# ATSAMA5D225CD1M device description
Architecture: CORTEX-A5; Family: SAMA5; Series: SAMA5D2
Registers are 32-bit, read-write, no defined reset value unless marked. A register's access mark holds for its fields unless they carry their own. Offsets are from the block's base; [hi:lo] are bit positions; {n}, {i} and the like mark numbered series.

## ACC — Analog Comparator Controller
Instances: ACC 0xF804A000
0x00 ACC_CR wo — Control Register
  [0] SWRST — Software Reset
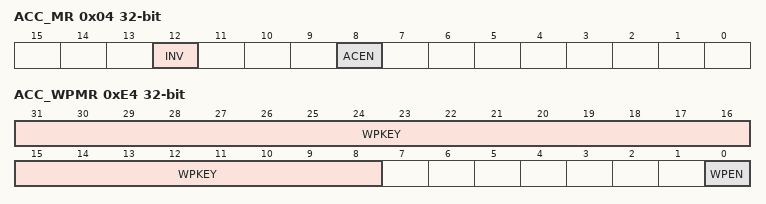
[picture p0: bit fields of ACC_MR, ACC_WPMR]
0x04 ACC_MR — Mode Register
  [12] INV — Invert Comparator Output
    0=DIS (Analog comparator output is directly processed.); 1=EN (Analog comparator output is inverted prior to being processed.)
  [8] ACEN — Analog Comparator Enable
    0=DIS (Analog comparator disabled.); 1=EN (Analog comparator enabled.)
0xE4 ACC_WPMR — Write Protection Mode Register
  [31:8] WPKEY — Write Protection Key
    0x414343=PASSWD (Writing any other value in this field aborts the write operation of the WPEN bit.Always reads as 0.)
  [0] WPEN — Write Protection Enable
0xE8 ACC_WPSR ro — Write Protection Status Register
  [0] WPVS — Write Protection Violation Status

## AESB — Advanced Encryption Standard Bridge
Instances: AESB 0xF001C000
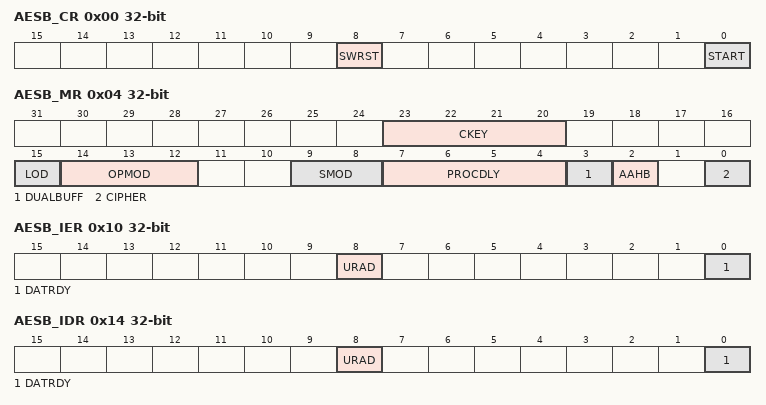
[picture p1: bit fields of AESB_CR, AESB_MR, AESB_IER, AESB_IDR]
0x00 AESB_CR wo — Control Register
  [8] SWRST — Software Reset
  [0] START — Start Processing
0x04 AESB_MR — Mode Register
  [23:20] CKEY — Key
    14=PASSWD (This field must be written with 0xE the first time that AESB_MR is programmed. For subsequent programming of the AESB_MR register, any value can be written, including that of 0xE.Always reads as 0.)
  [15] LOD — Last Output Data Mode
  [14:12] OPMOD — Operating Mode
    0=ECB (Electronic Code Book mode); 1=CBC (Cipher Block Chaining mode); 4=CTR (Counter mode (16-bit internal counter))
  [9:8] SMOD — Start Mode
    0=MANUAL_START (Manual mode); 1=AUTO_START (Auto mode); 2=IDATAR0_START (AESB_IDATAR0 access only Auto mode)
  [7:4] PROCDLY — Processing Delay
  [3] DUALBUFF — Dual Input Buffer
    0=INACTIVE (AESB_IDATARx cannot be written during processing of previous block.); 1=ACTIVE (AESB_IDATARx can be written during processing of previous block when SMOD = 0x2. It speeds up the overall runtime of large files.)
  [2] AAHB — Automatic Bridge Mode
  [0] CIPHER — Processing Mode
0x10 AESB_IER wo — Interrupt Enable Register
  [8] URAD — Unspecified Register Access Detection Interrupt Enable
  [0] DATRDY — Data Ready Interrupt Enable
0x14 AESB_IDR wo — Interrupt Disable Register
  [8] URAD — Unspecified Register Access Detection Interrupt Disable
  [0] DATRDY — Data Ready Interrupt Disable
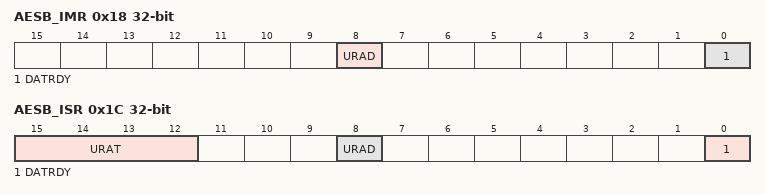
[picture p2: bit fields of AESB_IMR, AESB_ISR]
0x18 AESB_IMR ro — Interrupt Mask Register
  [8] URAD — Unspecified Register Access Detection Interrupt Mask
  [0] DATRDY — Data Ready Interrupt Mask
0x1C AESB_ISR ro — Interrupt Status Register
  [15:12] URAT — Unspecified Register Access
    0=IDR_WR_PROCESSING (Input Data Register written during the data processing when SMOD = 0x2 mode); 1=ODR_RD_PROCESSING (Output Data Register read during the data processing); 2=MR_WR_PROCESSING (Mode Register written during the data processing); 3=ODR_RD_SUBKGEN (Output Data Register read during the sub-keys generation); 4=MR_WR_SUBKGEN (Mode Register written during the sub-keys generation); 5=WOR_RD_ACCESS (Write-only register read access)
  [8] URAD — Unspecified Register Access Detection Status
  [0] DATRDY — Data Ready
{0x20+4i} AESB_KEYWR[{i}] (i=0..3) wo — Key Word Register
  [31:0] KEYW — Key Word
{0x40+4i} AESB_IDATAR[{i}] (i=0..3) wo — Input Data Register
  [31:0] IDATA — Input Data Word
{0x50+4i} AESB_ODATAR[{i}] (i=0..3) ro — Output Data Register
  [31:0] ODATA — Output Data
{0x60+4i} AESB_IVR[{i}] (i=0..3) wo — Initialization Vector Register
  [31:0] IV — Initialization Vector

## AIC — Advanced Interrupt Controller
Instances: AIC 0xFC020000, SAIC 0xF803C000
0x00 AIC_SSR — Source Select Register
  [6:0] INTSEL — Interrupt Line Selection
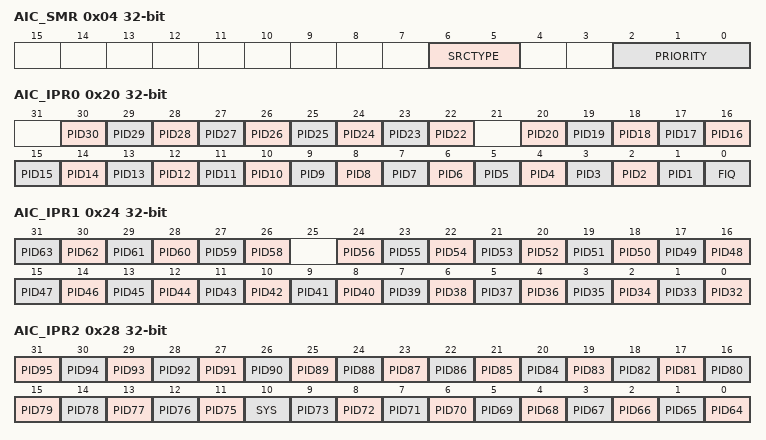
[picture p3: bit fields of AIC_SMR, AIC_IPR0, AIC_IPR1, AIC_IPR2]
0x04 AIC_SMR — Source Mode Register
  [6:5] SRCTYPE — Interrupt Source Type
    0=INT_LEVEL_SENSITIVE (High-level sensitive for internal source. Low-level sensitive for external source); 1=EXT_NEGATIVE_EDGE (Negative-edge triggered for external source); 2=EXT_HIGH_LEVEL (High-level sensitive for internal source. High-level sensitive for external source); 3=EXT_POSITIVE_EDGE (Positive-edge triggered for external source)
  [2:0] PRIORITY — Priority Level
    0=MINIMUM (Minimum priority); 1=VERY_LOW (Very low priority); 2=LOW (Low priority); 3=MEDIUM_LOW (Medium priority); 4=MEDIUM_HIGH (Medium-high priority); 5=HIGH (High priority); 6=VERY_HIGH (Very high priority); 7=MAXIMUM (Maximum priority)
0x08 AIC_SVR — Source Vector Register
  [31:0] VECTOR — Source Vector
0x10 AIC_IVR ro — Interrupt Vector Register
  [31:0] IRQV
0x14 AIC_FVR ro — FIQ Vector Register
  [31:0] FIQV
0x18 AIC_ISR ro — Interrupt Status Register
  [6:0] IRQID — Current Interrupt Identifier
0x20 AIC_IPR0 ro — Interrupt Pending Register 0
  [n] PID{n} (n=22..30) — Interrupt Pending
  [n] PID{n} (n=1..20) — Interrupt Pending
  [0] FIQ — Interrupt Pending
0x24 AIC_IPR1 ro — Interrupt Pending Register 1
  [n-32] PID{n} (n=58..63) — Interrupt Pending
  [n-32] PID{n} (n=32..56) — Interrupt Pending
0x28 AIC_IPR2 ro — Interrupt Pending Register 2
  [n-64] PID{n} (n=75..95) — Interrupt Pending
  [10] SYS — Interrupt Pending
  [n-64] PID{n} (n=64..73) — Interrupt Pending
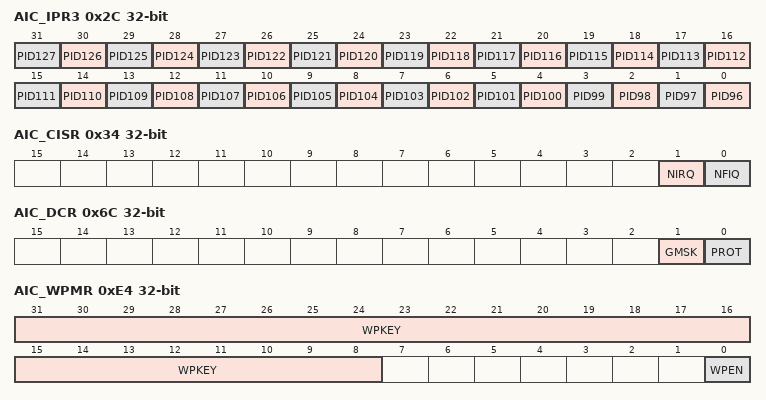
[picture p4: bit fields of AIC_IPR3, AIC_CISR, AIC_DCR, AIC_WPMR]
0x2C AIC_IPR3 ro — Interrupt Pending Register 3
  [n-96] PID{n} (n=96..127) — Interrupt Pending
0x30 AIC_IMR ro — Interrupt Mask Register
  [0] INTM — Interrupt Mask
0x34 AIC_CISR ro — Core Interrupt Status Register
  [1] NIRQ — NIRQ Status
  [0] NFIQ — NFIQ Status
0x38 AIC_EOICR wo — End of Interrupt Command Register
  [0] ENDIT — Interrupt Processing Complete Command
0x3C AIC_SPU — Spurious Interrupt Vector Register
  [31:0] SIVR
0x40 AIC_IECR wo — Interrupt Enable Command Register
  [0] INTEN — Interrupt Enable
0x44 AIC_IDCR wo — Interrupt Disable Command Register
  [0] INTD — Interrupt Disable
0x48 AIC_ICCR wo — Interrupt Clear Command Register
  [0] INTCLR — Interrupt Clear
0x4C AIC_ISCR wo — Interrupt Set Command Register
  [0] INTSET — Interrupt Set
0x6C AIC_DCR — Debug Control Register
  [1] GMSK — General Interrupt Mask
  [0] PROT — Protection Mode
0xE4 AIC_WPMR — Write Protection Mode Register
  [31:8] WPKEY — Write Protection Key
    0x414943=PASSWD (Writing any other value in this field aborts the write operation of the WPEN bit.Always reads as 0.)
  [0] WPEN — Write Protection Enable
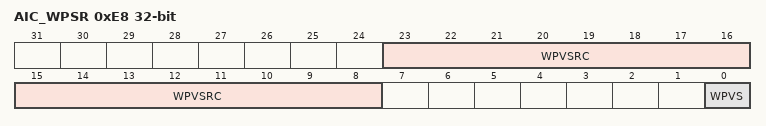
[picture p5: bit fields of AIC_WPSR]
0xE8 AIC_WPSR ro — Write Protection Status Register
  [23:8] WPVSRC — Write Protection Violation Source
  [0] WPVS — Write Protection Violation Status

## Notices in the file
Copyright (c) 2020 Microchip Technology Inc.
SPDX-License-Identifier: Apache-2.0
Licensed under the Apache License, Version 2.0 (the "License");
you may not use this file except in compliance with the License.
You may obtain a copy of the License at
http://www.apache.org/licenses/LICENSE-2.0
Unless required by applicable law or agreed to in writing, software
distributed under the License is distributed on an "AS IS" BASIS,
WITHOUT WARRANTIES OR CONDITIONS OF ANY KIND, either express or implied.
See the License for the specific language governing permissions and
limitations under the License.
